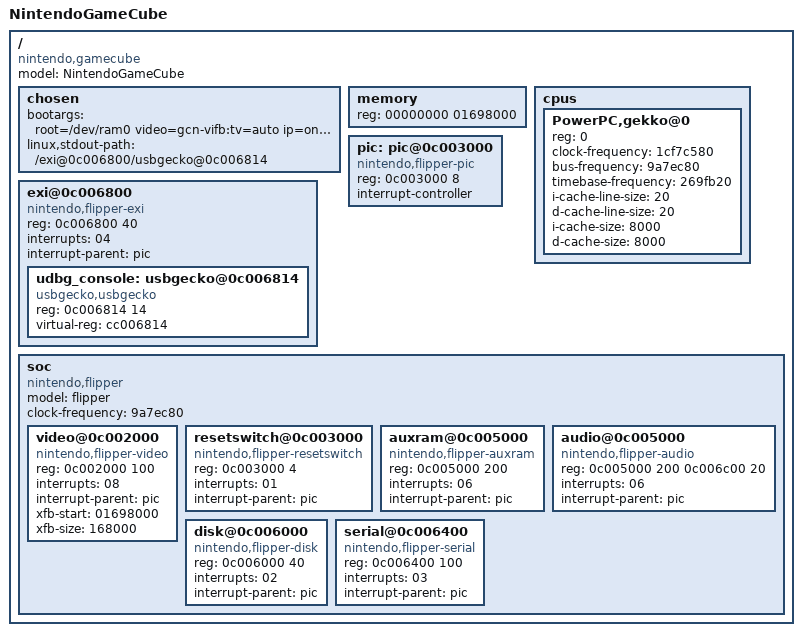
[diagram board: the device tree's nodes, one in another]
/*
 * arch/powerpc/boot/dts/gamecube.dts
 *
 * Nintendo GameCube platform device tree source
 * Copyright (C) 2007-2008 The GameCube Linux Team
 * Copyright (C) 2007,2008 Albert Herranz
 *
 * This program is free software; you can redistribute it and/or
 * modify it under the terms of the GNU General Public License
 * as published by the Free Software Foundation; either version 2
 * of the License, or (at your option) any later version.
 *
 */

/ {
	model = "NintendoGameCube";
	compatible = "nintendo,gamecube";
	#address-cells = <1>;
	#size-cells = <1>;

	chosen {
		bootargs = "root=/dev/ram0 video=gcn-vifb:tv=auto ip=on force_keyboard_port=4";
		linux,stdout-path = "/exi@0c006800/usbgecko@0c006814";
	};

	memory {
		device_type = "memory";
		/* 24M minus framebuffer memory area (640*576*2*2) */
		reg = <00000000 01698000>;
	};

	cpus {
		#address-cells = <1>;
		#size-cells = <0>;

		PowerPC,gekko@0 {
			device_type = "cpu";
			reg = <0>;
			clock-frequency = <1cf7c580>; /* 486MHz */
			bus-frequency = <9a7ec80>; /* 162MHz core-to-bus 3x */
			timebase-frequency = <269fb20>; /* 162MHz / 4 */
			/* Following required by dtc but not used */
			i-cache-line-size = <20>;
			d-cache-line-size = <20>;
			i-cache-size = <8000>;
			d-cache-size = <8000>;
		};
	};

	pic: pic@0c003000 {
		#interrupt-cells = <1>;
		compatible = "nintendo,flipper-pic";
		reg = <0c003000 8>;
		interrupt-controller;
	};

	/* External Interface bus */
	exi@0c006800 {
		#address-cells = <1>;
		#size-cells = <1>;
		compatible = "nintendo,flipper-exi";
		reg = <0c006800 40>;
		interrupts = <04>;
		interrupt-parent = <&pic>;

		udbg_console: usbgecko@0c006814 {
			compatible = "usbgecko,usbgecko";
			reg = <0c006814 14>;
			virtual-reg = <cc006814>;
		};
	};

	/* devices contained int the flipper chipset */
	soc {
		#address-cells = <1>;
		#size-cells = <1>;
		#interrupt-cells = <1>;
		model = "flipper";
		compatible = "nintendo,flipper";
		clock-frequency = <9a7ec80>; /* 162MHz */
		ranges = <0c000000 0c000000 00010000>;

		video@0c002000 {
			compatible = "nintendo,flipper-video";
			reg = <0c002000 100>;
			interrupts = <08>;
			interrupt-parent = <&pic>;
			xfb-start = <01698000>; /* end-of-ram - xfb-size */
			xfb-size = <168000>;
		};

		resetswitch@0c003000 {
			compatible = "nintendo,flipper-resetswitch";
			reg = <0c003000 4>;
			interrupts = <01>;
			interrupt-parent = <&pic>;
		};

		auxram@0c005000 {
			compatible = "nintendo,flipper-auxram";
			reg = <0c005000 200>;	/* DSP */
			interrupts = <06>;
			interrupt-parent = <&pic>;
		};

		audio@0c005000 {
			compatible = "nintendo,flipper-audio";
			reg = <0c005000 200	/* DSP */
			       0c006c00 20>;	/* AI */
			interrupts = <06>;
			interrupt-parent = <&pic>;
		};

		disk@0c006000 {
			compatible = "nintendo,flipper-disk";
			reg = <0c006000 40>;
			interrupts = <02>;
			interrupt-parent = <&pic>;
		};

		serial@0c006400 {
			compatible = "nintendo,flipper-serial";
			reg = <0c006400 100>;
			interrupts = <03>;
			interrupt-parent = <&pic>;
		};
        };
};

